# AST1060 register map
File version: 1.0
CPU: CM4 r0p1, little endian, MPU, FPU, 4 interrupt priority bits, 256 interrupts
Registers are 32-bit, read-write, reset 0x0 unless marked. A register's access mark holds for its fields unless they carry their own. Offsets are from the block's base; [hi:lo] are bit positions.

## uartdma
Base 0x7E79E000
0x00 UDMA000 — UART TX DMA enable
  [11:0] UARTTXDMAEnblReg — UART TX DMA enable register
  [3:0] UARTTXDMAEnblReg1 — UART TX DMA enable register
0x04 UDMA004 — UART RX DMA enable
  [11:0] UARTRXDMAEnblReg — UART RX DMA enable register
  [3:0] UARTRXDMAEnblReg1 — UART RX DMA enable register
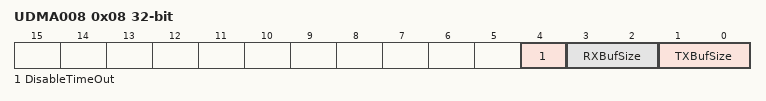
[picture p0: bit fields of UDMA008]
0x08 UDMA008 — Misc, buffer size
  [4] DisableTimeOut
  [3:2] RXBufSize — RX buffer size
  [1:0] TXBufSize — TX buffer size
0x0C UDMA00C — UART DMA time out timer
  [15:0] UARTDMATimeOutTimer
0x20 UDMA020 — UART TX DMA reset
  [11:0] UARTTXDMARst — UART TX DMA reset
  [3:0] UARTTXDMARst1 — UART TX DMA reset
0x24 UDMA024 — UART RX DMA reset
  [11:0] UARTRXDMARst — UART RX DMA reset
  [3:0] UARTRXDMARst1 — UART RX DMA reset
0x30 UDMA30 — UART TX DMA interrupt enable
  [11:0] UARTTXDMAINTEnbl — UART TX DMA interrupt enable
  [3:0] UARTTXDMAINTEnbl1 — UART TX DMA interrupt enable
0x34 UDMA034 — UART TX DMA interrupt status
  [11:0] UARTTXDMAINTSts — UART TX DMA interrupt status
  [3:0] UARTTXDMAINTSts1 — UART TX DMA interrupt status
0x38 UDMA038 — UART RX DMA interrupt enable
  [11:0] UARTRXDMAINTEnbl — UART RX DMA interrupt enable
  [3:0] UARTRXDMAINTEnbl1 — UART RX DMA interrupt enable
0x3C UDMA03C — UART RX DMA interrupt status
  [11:0] UARTRXDMAINTSts — UART RX DMA interrupt status
  [3:0] UARTRXDMAINTSts1 — UART RX DMA interrupt status
0x40 UDMA040 — UART1 TX read pointer
  [15:0] UART1TXReadPointer ro
0x44 UDMA044 — UART1 TX write pointer
  [15:0] UART1TXWrPointer
0x48 UDMA048 — UART1 TX buffer base address
  [15:0] UART1TXBufBaseAddr
0x4C UDMA0C4 — UART5 TX write pointer
  [15:0] UART5TXWrPointer
0x50 UDMA050 — UART1 RX read pointer
  [15:0] UART1RXReadPointer
0x54 UDMA054 — UART1 RX write pointer
  [15:0] UART1RXWrPointer ro
0x58 UDMA058 — UART1 RX buffer base address
  [15:0] UART1TXBufBaseAddr — UART1 TX buffer base address
0x60 UDMA060 — UART2 TX read pointer
  [15:0] UART2TXReadPointer ro
0x64 UDMA064 — UART2 TX write pointer
  [15:0] UART2TXWrPointer
0x68 UDMA068 — UART2 TX buffer base address
  [15:0] UART2TXBufBaseAddr
0x70 UDMA070 — UART2 RX read pointer
  [15:0] UART2RXReadPointer
0x74 UDMA074 — UART2 RX write pointer
  [15:0] UART2RXWrPointer ro
0x78 UDMA078 — UART2 RX buffer base address
  [15:0] UART2TXBufBaseAddr — UART2 TX buffer base address
0x80 UDMA080 — UART3 TX read pointer
  [15:0] UART3TXReadPointer ro
0x84 UDMA084 — UART3 TX write pointer
  [15:0] UART3TXWrPointer
0x88 UDMA088 — UART3 TX buffer base address
  [15:0] UART3TXBufBaseAddr
0x90 UDMA090 — UART3 RX read pointer
  [15:0] UART3RXReadPointer
0x94 UDMA094 — UART3 RX write pointer
  [15:0] UART3RXWrPointer ro
0x98 UDMA098 — UART3 RX buffer base address
  [15:0] UART3TXBufBaseAddr — UART3 TX buffer base address
0xA0 UDMA0A0 — UART4 TX read pointer
  [15:0] UART4TXReadPointer ro
0xA4 UDMA0A4 — UART4 TX write pointer
  [15:0] UART4TXWrPointer
0xA8 UDMA0A8 — UART4 TX buffer base address
  [15:0] UART4TXBufBaseAddr
0xB0 UDMA0B0 — UART4 RX read pointer
  [15:0] UART4RXReadPointer
0xB4 UDMA0B4 — UART4 RX write pointer
  [15:0] UART4RXWrPointer ro
0xB8 UDMA0B8 — UART4 RX buffer base address
  [15:0] UART4TXBufBaseAddr — UART4 TX buffer base address
0xC0 UDMA0C0 — UART5 TX read pointer
  [15:0] UART5TXReadPointer ro
0xC8 UDMA0C8 — UART5 TX buffer base address
  [15:0] UART5TXBufBaseAddr
0xD0 UDMA0D0 — UART5 RX read pointer
  [15:0] UART5RXReadPointer
0xD4 UDMA0D4 — UART5 RX write pointer
  [15:0] UART5RXWrPointer ro
0xD8 UDMA0D8 — UART5 RX buffer base address
  [15:0] UART5TXBufBaseAddr — UART5 TX buffer base address
0xE0 UDMA0E0 — UART6 TX read pointer
  [15:0] UART6TXReadPointer ro
0xE4 UDMA0E4 — UART6 TX write pointer
  [15:0] UART6TXWrPointer
0xE8 UDMA0E8 — UART6 TX buffer base address
  [15:0] UART6TXBufBaseAddr
0xF0 UDMA0F0 — UART6 RX read pointer
  [15:0] UART6RXReadPointer
0xF4 UDMA0F4 — UART6 RX write pointer
  [15:0] UART6RXWrPointer ro
0xF8 UDMA0F8 — UART6 RX buffer base address
  [15:0] UART6TXBufBaseAddr — UART6 TX buffer base address
0x100 UDMA100 — UART7 TX read pointer
  [15:0] UART7TXReadPointer ro
0x104 UDMA104 — UART7 TX write pointer
  [15:0] UART7TXWrPointer
0x108 UDMA108 — UART7 TX buffer base address
  [15:0] UART7TXBufBaseAddr
0x110 UDMA110 — UART7 RX read pointer
  [15:0] UART7RXReadPointer
0x114 UDMA114 — UART7 RX write pointer
  [15:0] UART7RXWrPointer ro
0x118 UDMA118 — UART7 RX buffer base address
  [15:0] UART7TXBufBaseAddr — UART7 TX buffer base address
0x120 UDMA120 — UART8 TX read pointer
  [15:0] UART8TXReadPointer ro
0x124 UDMA124 — UART8 TX write pointer
  [15:0] UART8TXWrPointer
0x128 UDMA128 — UART8 TX buffer base address
  [15:0] UART8TXBufBaseAddr
0x130 UDMA130 — UART8 RX read pointer
  [15:0] UART8RXReadPointer
0x134 UDMA134 — UART8 RX write pointer
  [15:0] UART8RXWrPointer ro
0x138 UDMA138 — UART8 RX buffer base address
  [15:0] UART8TXBufBaseAddr — UART8 TX buffer base address
0x140 UDMA140 — UART9 TX read pointer
  [15:0] UART9TXReadPointer ro
0x144 UDMA144 — UART9 TX write pointer
  [15:0] UART9TXWrPointer
0x148 UDMA148 — UART9 TX buffer base address
  [15:0] UART9TXBufBaseAddr
0x150 UDMA150 — UART9 RX read pointer
  [15:0] UART9RXReadPointer
0x154 UDMA154 — UART9 RX write pointer
  [15:0] UART9RXWrPointer ro
0x158 UDMA158 — UART9 RX buffer base address
  [15:0] UART9TXBufBaseAddr — UART9 TX buffer base address
0x160 UDMA160 — UART10 TX read pointer
  [15:0] UART10TXReadPointer ro
0x164 UDMA164 — UART10 TX write pointer
  [15:0] UART10TXWrPointer
0x168 UDMA168 — UART10 TX buffer base address
  [15:0] UART10TXBufBaseAddr
0x170 UDMA170 — UART10 RX read pointer
  [15:0] UART10RXReadPointer
0x174 UDMA174 — UART10 RX write pointer
  [15:0] UART10RXWrPointer ro
0x178 UDMA178 — UART10 RX buffer base address
  [15:0] UART10TXBufBaseAddr — UART10 TX buffer base address
0x180 UDMA180 — UART11 TX read pointer
  [15:0] UART11TXReadPointer ro
0x184 UDMA184 — UART11 TX write pointer
  [15:0] UART11TXWrPointer
0x188 UDMA188 — UART11 TX buffer base address
  [15:0] UART11TXBufBaseAddr
0x190 UDMA190 — UART11 RX read pointer
  [15:0] UART11RXReadPointer
0x194 UDMA194 — UART11 RX write pointer
  [15:0] UART11RXWrPointer ro
0x198 UDMA198 — UART11 RX buffer base address
  [15:0] UART11TXBufBaseAddr — UART11 TX buffer base address
0x1A0 UDMA1A0 — UART12 TX read pointer
  [15:0] UART12TXReadPointer ro
0x1A4 UDMA1A4 — UART12 TX write pointer
  [15:0] UART12TXWrPointer
0x1A8 UDMA1A8 — UART12 TX buffer base address
  [15:0] UART12TXBufBaseAddr
0x1B0 UDMA1B0 — UART12 RX read pointer
  [15:0] UART12RXReadPointer
0x1B4 UDMA1B4 — UART12 RX write pointer
  [15:0] UART12RXWrPointer ro
0x1B8 UDMA1B8 — UART12 RX buffer base address
  [15:0] UART12TXBufBaseAddr — UART12 TX buffer base address
